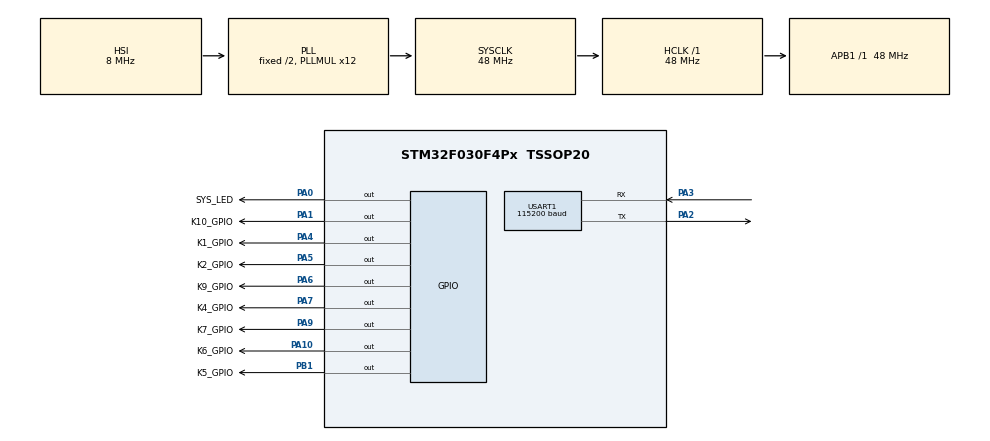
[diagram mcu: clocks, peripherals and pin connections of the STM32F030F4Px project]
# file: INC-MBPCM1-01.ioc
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FREERTOS.Tasks01=defaultTask,0,96,StartDefaultTask,Default,NULL,Dynamic,NULL,NULL;myTask01,0,96,usart_scan,Default,NULL,Dynamic,NULL,NULL
Mcu.Family=STM32F0
Mcu.Name=STM32F030F4Px
Mcu.Package=TSSOP20
NVIC.TIM1_BRK_UP_TRG_COM_IRQn=true\:0\:0\:false\:false\:true\:false\:false
NVIC.TimeBase=TIM1_BRK_UP_TRG_COM_IRQn
NVIC.TimeBaseIP=TIM1
NVIC.USART1_IRQn=true\:3\:0\:false\:false\:true\:true\:true
PA0.GPIO_Label=SYS_LED
PA0.Signal=GPIO_Output
PA1.GPIO_Label=K10_GPIO
PA1.Signal=GPIO_Output
PA10.GPIO_Label=K6_GPIO
PA10.Signal=GPIO_Output
PA13.Mode=Serial_Wire
PA13.Signal=SYS_SWDIO
PA14.Mode=Serial_Wire
PA14.Signal=SYS_SWCLK
PA2.Mode=Asynchronous
PA2.Signal=USART1_TX
PA3.Mode=Asynchronous
PA3.Signal=USART1_RX
PA4.GPIO_Label=K1_GPIO
PA4.Signal=GPIO_Output
PA5.GPIO_Label=K2_GPIO
PA5.Signal=GPIO_Output
PA6.GPIO_Label=K9_GPIO
PA6.Signal=GPIO_Output
PA7.GPIO_Label=K4_GPIO
PA7.Signal=GPIO_Output
PA9.GPIO_Label=K7_GPIO
PA9.Signal=GPIO_Output
PB1.GPIO_Label=K5_GPIO
PB1.Signal=GPIO_Output
PF0-OSC_IN.Mode=HSE-External-Oscillator
PF0-OSC_IN.Signal=RCC_OSC_IN
PF1-OSC_OUT.Mode=HSE-External-Oscillator
PF1-OSC_OUT.Signal=RCC_OSC_OUT
ProjectManager.HeapSize=0x200
ProjectManager.StackSize=0x400
ProjectManager.TargetToolchain=MDK-ARM V5
RCC.AHBFreq_Value=48000000
RCC.APB1Freq_Value=48000000
RCC.APB1TimFreq_Value=48000000
RCC.HCLKFreq_Value=48000000
RCC.HSE_Timout=200
RCC.PLLMUL=RCC_PLL_MUL12
RCC.SYSCLKFreq_VALUE=48000000
RCC.SYSCLKSource=RCC_SYSCLKSOURCE_PLLCLK
USART1.BaudRate=115200
USART1.VirtualMode-Asynchronous=VM_ASYNC
VP_FREERTOS_VS_ENABLE.Mode=Enabled
VP_SYS_VS_tim1.Mode=TIM1
board=custom

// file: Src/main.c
/**
  ******************************************************************************
  * @file           : main.c
  * @brief          : Main program body
  ******************************************************************************
  * This notice applies to any and all portions of this file
  * that are not between comment pairs USER CODE BEGIN and
  * USER CODE END. Other portions of this file, whether
  * inserted by the user or by software development tools
  * are owned by their respective copyright owners.
  *
  * Copyright (c) 2018 STMicroelectronics International N.V.
  * All rights reserved.
  *
  * Redistribution and use in source and binary forms, with or without
  * modification, are permitted, provided that the following conditions are met:
  *
  * 1. Redistribution of source code must retain the above copyright notice,
  *    this list of conditions and the following disclaimer.
  * 2. Redistributions in binary form must reproduce the above copyright notice,
  *    this list of conditions and the following disclaimer in the documentation
  *    and/or other materials provided with the distribution.
  * 3. Neither the name of STMicroelectronics nor the names of other
  *    contributors to this software may be used to endorse or promote products
  *    derived from this software without specific written permission.
  * 4. This software, including modifications and/or derivative works of this
  *    software, must execute solely and exclusively on microcontroller or
  *    microprocessor devices manufactured by or for STMicroelectronics.
  * 5. Redistribution and use of this software other than as permitted under
  *    this license is void and will automatically terminate your rights under
  *    this license.
  *
  * THIS SOFTWARE IS PROVIDED BY STMICROELECTRONICS AND CONTRIBUTORS "AS IS"
  * AND ANY EXPRESS, IMPLIED OR STATUTORY WARRANTIES, INCLUDING, BUT NOT
  * LIMITED TO, THE IMPLIED WARRANTIES OF MERCHANTABILITY, FITNESS FOR A
  * PARTICULAR PURPOSE AND NON-INFRINGEMENT OF THIRD PARTY INTELLECTUAL PROPERTY
  * RIGHTS ARE DISCLAIMED TO THE FULLEST EXTENT PERMITTED BY LAW. IN NO EVENT
  * SHALL STMICROELECTRONICS OR CONTRIBUTORS BE LIABLE FOR ANY DIRECT, INDIRECT,
  * INCIDENTAL, SPECIAL, EXEMPLARY, OR CONSEQUENTIAL DAMAGES (INCLUDING, BUT NOT
  * LIMITED TO, PROCUREMENT OF SUBSTITUTE GOODS OR SERVICES; LOSS OF USE, DATA,
  * OR PROFITS; OR BUSINESS INTERRUPTION) HOWEVER CAUSED AND ON ANY THEORY OF
  * LIABILITY, WHETHER IN CONTRACT, STRICT LIABILITY, OR TORT (INCLUDING
  * NEGLIGENCE OR OTHERWISE) ARISING IN ANY WAY OUT OF THE USE OF THIS SOFTWARE,
  * EVEN IF ADVISED OF THE POSSIBILITY OF SUCH DAMAGE.
  *
  ******************************************************************************
  */
#include "main.h"
#include "stm32f0xx_hal.h"
#include "cmsis_os.h"
#include "usart.h"
#include "gpio.h"

/* USER CODE BEGIN Includes */
#include "usmart.h"
#include "usmart_str.h"
#include <stdlib.h>
/* USER CODE END Includes */

/* USER CODE BEGIN PV */
/* Private variables ---------------------------------------------------------*/

/* USER CODE END PV */

void SystemClock_Config(void);
void MX_FREERTOS_Init(void);

/* USER CODE BEGIN PFP */
/* Private function prototypes -----------------------------------------------*/

/* USER CODE END PFP */

int main(void)
{
  /* USER CODE BEGIN 1 */
	//u32 BlinkDelay;
  /* USER CODE END 1 */

  /* MCU Configuration----------------------------------------------------------*/

  /* Reset of all peripherals, Initializes the Flash interface and the Systick. */
  HAL_Init();

  /* Configure the system clock */
  SystemClock_Config();

  /* Initialize all configured peripherals */
  MX_GPIO_Init();
  MX_USART1_UART_Init();
  /* USER CODE BEGIN 2 */

	usmart_dev.init(0);
	printf(" controller init ok\r\n>>");
	HAL_UART_Receive_IT(&huart1, (u8 *)aRxBuffer, 1);
  /* USER CODE END 2 */

  /* Call init function for freertos objects (in freertos.c) */
  MX_FREERTOS_Init();

  /* Start scheduler */
  osKernelStart();

  /* We should never get here as control is now taken by the scheduler */

  /* Infinite loop */
  /* USER CODE BEGIN WHILE */
	//BlinkDelay=HAL_GetTick();

  while (1)
  {

  /* USER CODE END WHILE */

  /* USER CODE BEGIN 3 */

//		if(abs((int)(HAL_GetTick()-BlinkDelay))>350)
//  	{
//  		BlinkDelay=HAL_GetTick();
//		}
		//usmart_dev.scan();

  }
  /* USER CODE END 3 */

}

void SystemClock_Config(void)
{

  RCC_OscInitTypeDef RCC_OscInitStruct;
  RCC_ClkInitTypeDef RCC_ClkInitStruct;
  RCC_PeriphCLKInitTypeDef PeriphClkInit;

    /**Initializes the CPU, AHB and APB busses clocks
    */
  RCC_OscInitStruct.OscillatorType = RCC_OSCILLATORTYPE_HSI;
  RCC_OscInitStruct.HSIState = RCC_HSI_ON;
  RCC_OscInitStruct.HSICalibrationValue = 16;
  RCC_OscInitStruct.PLL.PLLState = RCC_PLL_ON;
  RCC_OscInitStruct.PLL.PLLSource = RCC_PLLSOURCE_HSI;
  RCC_OscInitStruct.PLL.PLLMUL = RCC_PLL_MUL12;
  RCC_OscInitStruct.PLL.PREDIV = RCC_PREDIV_DIV1;
  if (HAL_RCC_OscConfig(&RCC_OscInitStruct) != HAL_OK)
  {
    _Error_Handler(__FILE__, __LINE__);
  }

    /**Initializes the CPU, AHB and APB busses clocks
    */
  RCC_ClkInitStruct.ClockType = RCC_CLOCKTYPE_HCLK|RCC_CLOCKTYPE_SYSCLK
                              |RCC_CLOCKTYPE_PCLK1;
  RCC_ClkInitStruct.SYSCLKSource = RCC_SYSCLKSOURCE_PLLCLK;
  RCC_ClkInitStruct.AHBCLKDivider = RCC_SYSCLK_DIV1;
  RCC_ClkInitStruct.APB1CLKDivider = RCC_HCLK_DIV1;

  if (HAL_RCC_ClockConfig(&RCC_ClkInitStruct, FLASH_LATENCY_1) != HAL_OK)
  {
    _Error_Handler(__FILE__, __LINE__);
  }

  PeriphClkInit.PeriphClockSelection = RCC_PERIPHCLK_USART1;
  PeriphClkInit.Usart1ClockSelection = RCC_USART1CLKSOURCE_PCLK1;
  if (HAL_RCCEx_PeriphCLKConfig(&PeriphClkInit) != HAL_OK)
  {
    _Error_Handler(__FILE__, __LINE__);
  }

    /**Configure the Systick interrupt time
    */
  HAL_SYSTICK_Config(HAL_RCC_GetHCLKFreq()/1000);

    /**Configure the Systick
    */
  HAL_SYSTICK_CLKSourceConfig(SYSTICK_CLKSOURCE_HCLK);

  /* SysTick_IRQn interrupt configuration */
  HAL_NVIC_SetPriority(SysTick_IRQn, 3, 0);
}

void HAL_TIM_PeriodElapsedCallback(TIM_HandleTypeDef *htim)
{
  if (htim->Instance == TIM1) {
    HAL_IncTick();
  }
}

void _Error_Handler(char *file, int line)
{
  while(1)
  {
  }
}

/************************ (C) COPYRIGHT STMicroelectronics *****END OF FILE****/

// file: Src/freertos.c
/**
  ******************************************************************************
  * File Name          : freertos.c
  * Description        : Code for freertos applications
  ******************************************************************************
  * This notice applies to any and all portions of this file
  * that are not between comment pairs USER CODE BEGIN and
  * USER CODE END. Other portions of this file, whether
  * inserted by the user or by software development tools
  * are owned by their respective copyright owners.
  *
  * Copyright (c) 2018 STMicroelectronics International N.V.
  * All rights reserved.
  *
  * Redistribution and use in source and binary forms, with or without
  * modification, are permitted, provided that the following conditions are met:
  *
  * 1. Redistribution of source code must retain the above copyright notice,
  *    this list of conditions and the following disclaimer.
  * 2. Redistributions in binary form must reproduce the above copyright notice,
  *    this list of conditions and the following disclaimer in the documentation
  *    and/or other materials provided with the distribution.
  * 3. Neither the name of STMicroelectronics nor the names of other
  *    contributors to this software may be used to endorse or promote products
  *    derived from this software without specific written permission.
  * 4. This software, including modifications and/or derivative works of this
  *    software, must execute solely and exclusively on microcontroller or
  *    microprocessor devices manufactured by or for STMicroelectronics.
  * 5. Redistribution and use of this software other than as permitted under
  *    this license is void and will automatically terminate your rights under
  *    this license.
  *
  * THIS SOFTWARE IS PROVIDED BY STMICROELECTRONICS AND CONTRIBUTORS "AS IS"
  * AND ANY EXPRESS, IMPLIED OR STATUTORY WARRANTIES, INCLUDING, BUT NOT
  * LIMITED TO, THE IMPLIED WARRANTIES OF MERCHANTABILITY, FITNESS FOR A
  * PARTICULAR PURPOSE AND NON-INFRINGEMENT OF THIRD PARTY INTELLECTUAL PROPERTY
  * RIGHTS ARE DISCLAIMED TO THE FULLEST EXTENT PERMITTED BY LAW. IN NO EVENT
  * SHALL STMICROELECTRONICS OR CONTRIBUTORS BE LIABLE FOR ANY DIRECT, INDIRECT,
  * INCIDENTAL, SPECIAL, EXEMPLARY, OR CONSEQUENTIAL DAMAGES (INCLUDING, BUT NOT
  * LIMITED TO, PROCUREMENT OF SUBSTITUTE GOODS OR SERVICES; LOSS OF USE, DATA,
  * OR PROFITS; OR BUSINESS INTERRUPTION) HOWEVER CAUSED AND ON ANY THEORY OF
  * LIABILITY, WHETHER IN CONTRACT, STRICT LIABILITY, OR TORT (INCLUDING
  * NEGLIGENCE OR OTHERWISE) ARISING IN ANY WAY OUT OF THE USE OF THIS SOFTWARE,
  * EVEN IF ADVISED OF THE POSSIBILITY OF SUCH DAMAGE.
  *
  ******************************************************************************
  */

#include "FreeRTOS.h"
#include "task.h"
#include "cmsis_os.h"

/* USER CODE BEGIN Includes */
#include "usmart.h"
#include "usmart_str.h"
/* USER CODE END Includes */

osThreadId defaultTaskHandle;
osThreadId myTask01Handle;

void StartDefaultTask(void const * argument);
void usart_scan(void const * argument);

void MX_FREERTOS_Init(void); /* (MISRA C 2004 rule 8.1) */

/* Hook prototypes */

/* Init FreeRTOS */

void MX_FREERTOS_Init(void) {

  /* Create the thread(s) */
  /* definition and creation of defaultTask */
  osThreadDef(defaultTask, StartDefaultTask, osPriorityNormal, 0, 96);
  defaultTaskHandle = osThreadCreate(osThread(defaultTask), NULL);

  /* definition and creation of myTask01 */
  osThreadDef(myTask01, usart_scan, osPriorityNormal, 0, 96);
  myTask01Handle = osThreadCreate(osThread(myTask01), NULL);

}

/* StartDefaultTask function */
void StartDefaultTask(void const * argument)
{

  /* USER CODE BEGIN StartDefaultTask */
  /* Infinite loop */
  for(;;)
  {
//		GPIOB->ODR ^= BIT12;
//		GPIOD->BRR = BIT7;
//		GPIOD->BSRR = BIT7 ;
//		GPIOA->ODR ^= BIT0;
		HAL_GPIO_TogglePin(SYS_LED_GPIO_Port,SYS_LED_Pin);
    osDelay(350);
  }
  /* USER CODE END StartDefaultTask */
}

/* usart_scan function */
void usart_scan(void const * argument)
{
  /* USER CODE BEGIN usart_scan */
  /* Infinite loop */
  for(;;)
  {
		usmart_dev.scan();
    osDelay(1);
  }
  /* USER CODE END usart_scan */
}

/************************ (C) COPYRIGHT STMicroelectronics *****END OF FILE****/
